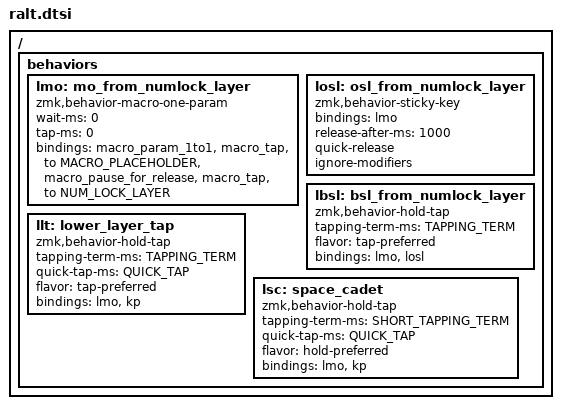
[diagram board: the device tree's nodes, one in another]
#define EZ_LSL(layer)  lbsl (layer) (layer)
#define SYM_ALT &EZ_SK(RALT)
#define SYM_ALT_NAV &EZ_LSL(SYMBOLS_LAYER)

/ {
  behaviors {
    lmo: mo_from_numlock_layer {
      compatible = "zmk,behavior-macro-one-param";
      wait-ms = <0>;
      tap-ms = <0>;
      #binding-cells = <1>;
      bindings =
        <&macro_param_1to1>,
        <&macro_tap &to MACRO_PLACEHOLDER>,
        <&macro_pause_for_release>,
        <&macro_tap &to NUM_LOCK_LAYER>;
    }; 
    losl: osl_from_numlock_layer {
      compatible = "zmk,behavior-sticky-key";
      #binding-cells = <1>;
      bindings = <&lmo>;
      release-after-ms = <1000>;
      quick-release;
      ignore-modifiers;
    };
    lbsl: bsl_from_numlock_layer {
      compatible = "zmk,behavior-hold-tap";
      #binding-cells = <2>;
      tapping-term-ms = <TAPPING_TERM>;
      flavor = "tap-preferred";
      bindings = <&lmo>, <&losl>;
    };
    llt: lower_layer_tap { // same as lt, but from numlock_layer
      compatible = "zmk,behavior-hold-tap";
      #binding-cells = <2>;
      tapping-term-ms = <TAPPING_TERM>;
      quick-tap-ms = <QUICK_TAP>;
      flavor = "tap-preferred";
      bindings = <&lmo>, <&kp>;
    };    
    lsc: space_cadet { // same as sc, but from numlock_layer
      compatible = "zmk,behavior-hold-tap";
      #binding-cells = <2>;
      tapping-term-ms = <SHORT_TAPPING_TERM>;
      quick-tap-ms = <QUICK_TAP>;
      flavor = "hold-preferred";
      bindings = <&lmo>, <&kp>;
    };
    
  };
};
